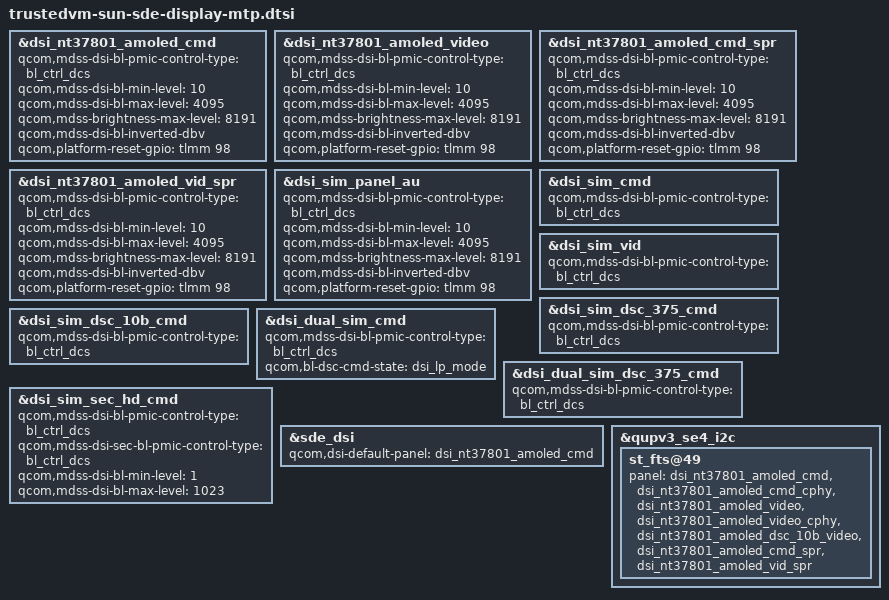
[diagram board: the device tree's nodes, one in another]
// SPDX-License-Identifier: BSD-3-Clause
/*
 * Copyright (c) 2023-2024 Qualcomm Innovation Center, Inc. All rights reserved.
 */

#include "trustedvm-sun-sde-display.dtsi"

&dsi_nt37801_amoled_cmd {
	qcom,mdss-dsi-bl-pmic-control-type = "bl_ctrl_dcs";
	qcom,mdss-dsi-bl-min-level = <10>;
	qcom,mdss-dsi-bl-max-level = <4095>;
	qcom,mdss-brightness-max-level = <8191>;
	qcom,mdss-dsi-bl-inverted-dbv;
	qcom,platform-reset-gpio = <&tlmm 98 0>;
};

&dsi_nt37801_amoled_video {
	qcom,mdss-dsi-bl-pmic-control-type = "bl_ctrl_dcs";
	qcom,mdss-dsi-bl-min-level = <10>;
	qcom,mdss-dsi-bl-max-level = <4095>;
	qcom,mdss-brightness-max-level = <8191>;
	qcom,mdss-dsi-bl-inverted-dbv;
	qcom,platform-reset-gpio = <&tlmm 98 0>;
};

&dsi_nt37801_amoled_cmd_spr {
	qcom,mdss-dsi-bl-pmic-control-type = "bl_ctrl_dcs";
	qcom,mdss-dsi-bl-min-level = <10>;
	qcom,mdss-dsi-bl-max-level = <4095>;
	qcom,mdss-brightness-max-level = <8191>;
	qcom,mdss-dsi-bl-inverted-dbv;
	qcom,platform-reset-gpio = <&tlmm 98 0>;
};

&dsi_nt37801_amoled_vid_spr {
	qcom,mdss-dsi-bl-pmic-control-type = "bl_ctrl_dcs";
	qcom,mdss-dsi-bl-min-level = <10>;
	qcom,mdss-dsi-bl-max-level = <4095>;
	qcom,mdss-brightness-max-level = <8191>;
	qcom,mdss-dsi-bl-inverted-dbv;
	qcom,platform-reset-gpio = <&tlmm 98 0>;
};

&dsi_sim_panel_au {
	qcom,mdss-dsi-bl-pmic-control-type = "bl_ctrl_dcs";
	qcom,mdss-dsi-bl-min-level = <10>;
	qcom,mdss-dsi-bl-max-level = <4095>;
	qcom,mdss-brightness-max-level = <8191>;
	qcom,mdss-dsi-bl-inverted-dbv;
	qcom,platform-reset-gpio = <&tlmm 98 0>;
};

&dsi_sim_cmd {
	qcom,mdss-dsi-bl-pmic-control-type = "bl_ctrl_dcs";
};

&dsi_sim_vid {
	qcom,mdss-dsi-bl-pmic-control-type = "bl_ctrl_dcs";
};

&dsi_sim_dsc_375_cmd {
	qcom,mdss-dsi-bl-pmic-control-type = "bl_ctrl_dcs";
};

&dsi_sim_dsc_10b_cmd {
	qcom,mdss-dsi-bl-pmic-control-type = "bl_ctrl_dcs";
};

&dsi_dual_sim_cmd {
	qcom,mdss-dsi-bl-pmic-control-type = "bl_ctrl_dcs";
	qcom,bl-dsc-cmd-state = "dsi_lp_mode";
};

&dsi_dual_sim_dsc_375_cmd {
	qcom,mdss-dsi-bl-pmic-control-type = "bl_ctrl_dcs";
};

&dsi_sim_sec_hd_cmd {
	qcom,mdss-dsi-bl-pmic-control-type = "bl_ctrl_dcs";
	qcom,mdss-dsi-sec-bl-pmic-control-type = "bl_ctrl_dcs";
	qcom,mdss-dsi-bl-min-level = <1>;
	qcom,mdss-dsi-bl-max-level = <1023>;
};

&sde_dsi {
	qcom,dsi-default-panel = <&dsi_nt37801_amoled_cmd>;
};

&qupv3_se4_i2c {
	st_fts@49 {
		panel = <&dsi_nt37801_amoled_cmd
			&dsi_nt37801_amoled_cmd_cphy
			&dsi_nt37801_amoled_video
			&dsi_nt37801_amoled_video_cphy
			&dsi_nt37801_amoled_dsc_10b_video
			&dsi_nt37801_amoled_cmd_spr
			&dsi_nt37801_amoled_vid_spr>;
	};
};
